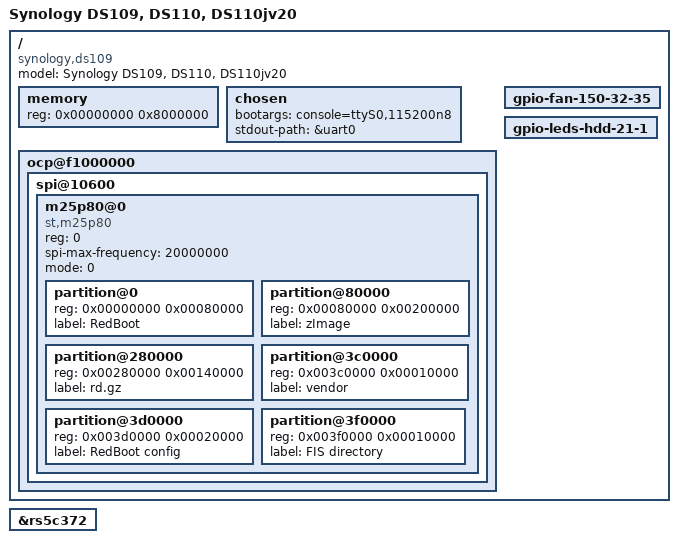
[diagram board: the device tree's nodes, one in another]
// SPDX-License-Identifier: GPL-2.0
/*
 * Andrew Lunn <andrew@lunn.ch>
 * Ben Peddell <klightspeed@killerwolves.net>
 *
 */

/dts-v1/;

#include "kirkwood.dtsi"
#include "kirkwood-6281.dtsi"
#include "kirkwood-synology.dtsi"

/ {
	model = "Synology DS109, DS110, DS110jv20";
	compatible = "synology,ds109", "synology,ds110jv20",
		     "synology,ds110", "marvell,kirkwood";

	memory {
		device_type = "memory";
		reg = <0x00000000 0x8000000>;
	};

	chosen {
		bootargs = "console=ttyS0,115200n8";
		stdout-path = &uart0;
	};

	ocp@f1000000 {
		spi@10600 {
			status = "okay";

			m25p80@0 {
				#address-cells = <1>;
				#size-cells = <1>;
				compatible = "st,m25p80", "jedec,spi-nor";
				reg = <0>;
				spi-max-frequency = <20000000>;
				mode = <0>;

				partition@0 {
					reg = <0x00000000 0x00080000>;
					label = "RedBoot";
				};

				partition@80000 {
					reg = <0x00080000 0x00200000>;
					label = "zImage";
				};

				partition@280000 {
					reg = <0x00280000 0x00140000>;
					label = "rd.gz";
				};

				partition@3c0000 {
					reg = <0x003c0000 0x00010000>;
					label = "vendor";
				};

				partition@3d0000 {
					reg = <0x003d0000 0x00020000>;
					label = "RedBoot config";
				};

				partition@3f0000 {
					reg = <0x003f0000 0x00010000>;
					label = "FIS directory";
				};
			};
		};
	};

	gpio-fan-150-32-35 {
		status = "okay";
	};

	gpio-leds-hdd-21-1 {
		status = "okay";
	};
};

&rs5c372 {
	status = "okay";
};
